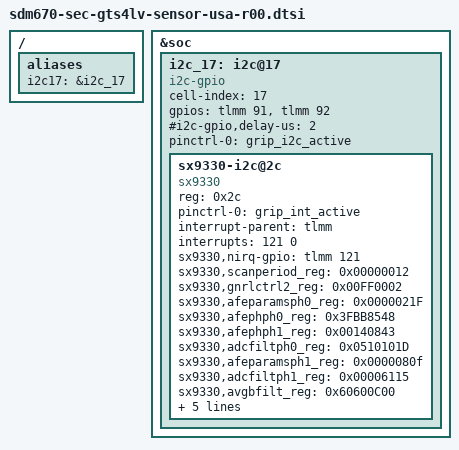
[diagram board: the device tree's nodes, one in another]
/* Copyright (c) 2013-2014, The Linux Foundation. All rights reserved.
 *
 * This program is free software; you can redistribute it and/or modify
 * it under the terms of the GNU General Public License version 2 and
 * only version 2 as published by the Free Software Foundation.
 *
 * This program is distributed in the hope that it will be useful,
 * but WITHOUT ANY WARRANTY; without even the implied warranty of
 * MERCHANTABILITY or FITNESS FOR A PARTICULAR PURPOSE.  See the
 * GNU General Public License for more details.
 */

/{
	aliases {
		i2c17 = &i2c_17;
	};
};

&soc {
	/* Main Grip Sensor */
	i2c_17: i2c@17 { /* SW I2C */
		status = "ok";

		cell-index = <17>;
		compatible = "i2c-gpio";
		gpios = <&tlmm 91 0 /* sda */
			 &tlmm 92 0 /* scl */>;
		#i2c-gpio,delay-us = <2>;
		#address-cells = <1>;
		#size-cells = <0>;
		pinctrl-names = "default";
		pinctrl-0 = <&grip_i2c_active>;

		sx9330-i2c@2c {
			compatible = "sx9330";
			reg = <0x2c>;
			pinctrl-names = "default";
			pinctrl-0 = <&grip_int_active>;

			interrupt-parent = <&tlmm>;
			interrupts = <121 0>;

			sx9330,nirq-gpio = <&tlmm 121 0>;

			sx9330,scanperiod_reg = <0x00000012>; /* scanperiod : 36ms */
			sx9330,gnrlctrl2_reg = <0x00FF0002>;
			sx9330,afeparamsph0_reg = <0x0000021F>;
			sx9330,afephph0_reg = <0x3FBB8548>;
			sx9330,afephph1_reg = <0x00140843>; /* compensation offset : 2115 */
			sx9330,adcfiltph0_reg = <0x0510101D>;
			sx9330,afeparamsph1_reg = <0x0000080f>; /* again : 3.3pF, sampling freq : 200.00 khz */
			sx9330,adcfiltph1_reg = <0x00006115>;    /* threshold : 4998, strength of RAW filter : 0  */
			sx9330,avgbfilt_reg = <0x60600C00>;   /* AVGPOSFILT : 1/256, AVGNEGFILT : 1/2 */
			sx9330,avgafilt_reg = <0x00000000>;
			sx9330,advdig3_reg = <0x00000000>;
			sx9330,advdig4_reg = <0x00000000>;
			sx9330,refcorra_reg = <0x00000000>;
			sx9330,touchthd_ta_reg = <0x0000E000>; /* adcfiltph1 mask - threshold : 25088 */
		};
	};
};
